# sdio_card_fn1_secure register map
Vendor: Texas Instruments
Peripheral module from a debugger description file (folder CC35X1E).
Registers are 32-bit, access per field, reset 0x0 unless marked. A register's access mark holds for its fields unless they carry their own. Offsets are as the file gives them; lines under a group give offsets from that group; [hi:lo] are bit positions; {n}, {i} and the like mark numbered series; 'fields as' and 'values as' point back to an identical list; <NAME> marks a mode.

## sdio_card_fn1_secure
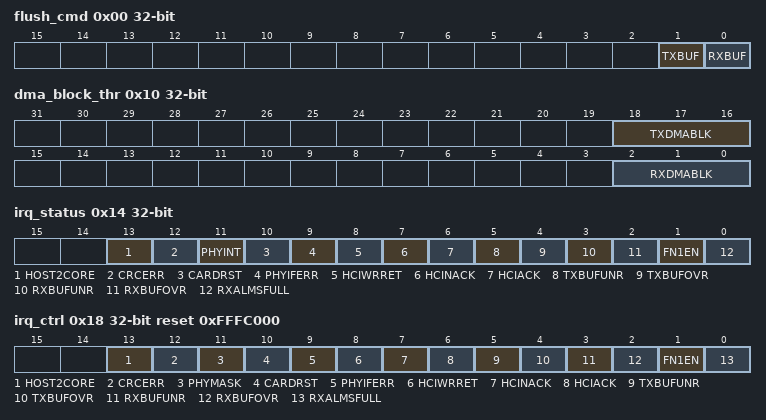
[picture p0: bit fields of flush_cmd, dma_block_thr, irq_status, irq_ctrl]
0x00 flush_cmd — A write only register. Flush command of the RX / TX buffers
  [1] TXBUF wo — TX BUFFER FLUSH: Writing to this address triggers the flush command of the TX buffer (data value is irrelevant).
  [0] RXBUF wo — RX BUFFER FLUSH: Writing to this address triggers the flush command of the RX buffer (data value is irrelevant).
0x04 rx_full_thr reset 0x410 — A R/W register that stores one of the RX buffer thresholds.
  [7:2] VAL rw — Buffer almost full threshold - When passing threshold an interrupt is generated (used by the software to indicate packets in buffer) The threshold is configured to allow receiving a completer packet header including packet length. Typical packet header could be 1 - 128 Bytes however the threshold must be 32bits aligned since SDIO FIFO supports 32bits aligned read only.
0x0C tx_irq_trig_thr reset 0x8080 — TX IRQ TRIG THR: A R/W register that stores the Threshold in bytes to raise host irq.
  [7:0] VAL rw — 8-bit value describing the number of bytes needed to trigger host irq 1. If HCI packet length > SDIO block (128-bytes) trigger is set to 128 Byte (entire block) 2. If HCI packet length < SDIO block, FW sets packet length in bytes as the trigger value
0x10 dma_block_thr reset not defined — A R/W register setting the BLOCK SIZE for the RX and TX DMA flow control
  [18:16] TXDMABLK rw — TX DMA BLOCK SIZE SEL: HOST reads from FIFO Determine when to assert flow control to DMA. The flow should be asserted when FIFO has enough free buffer >= Threshold. The threshold is determined according to the DMA block size 0 - 4 Bytes 1 - 8 Bytes 2 - 16 Bytes (Default) 3 - 32 Bytes 4 - 64 Bytes 5 - 128 Bytes 6,7 - Reserved
  [2:0] RXDMABLK rw — RX DMA BLOCK SIZE SEL: HOST Writes to FIFO Determine when to assert flow control to DMA. The flow should be asserted when num of bytes in FIFO > Threshold. The threshold is determined according to the DMA block size 0 - 4 Bytes 1 - 8 Bytes 2 - 16 Bytes (Default) 3 - 32 Bytes 4 - 64 Bytes 5 - 128 Bytes 6,7 - Reserved HOST Writes to FIFO Determine when to assert flow control to DMA. The flow should be asserted when num of bytes in FIFO > Threshold. The threshold is determined according to the DMA block size 0 - 4 Bytes 1 - 8 Bytes 2 - 16 Bytes (Default) 3 - 32 Bytes 4 - 64 Bytes 5 - 128 Bytes 6,7 - Reserved
0x14 irq_status ro — A RO register. Holds the status of the different interrupts of the SDIO. This register is cleared by writing to IRQ_CLEAR register Each interrupt is set when the event is active. In the case of ACKINT the software has to read the ACKNAK bit value to see if an ACK event was received or a read retry is starting.
  [13] HOST2CORE — Host to Card 15 bit message ready indication
  [12] CRCERR — '1' = CRC Error was detected for rx flow
  [11] PHYINT — SDIO PHY interrupt
  [10] CARDRST — Card Reset interrupt
  [9] PHYIFERR — Error in the OCP interface of the SDIO PHY
  [8] HCIWRRET — HCI packet write retry
  [7] HCINACK — HCI packet NACK interrupt
  [6] HCIACK — HCI packet ACK interrupt
  [5] TXBUFUNR — TX Buffer under-run interrupt
  [4] TXBUFOVR — TX Buffer overrun interrupt
  [3] RXBUFUNR — RX Buffer under-run interrupt
  [2] RXBUFOVR — RX Buffer overrun interrupt
  [1] FN1EN — Function #1 enable interrupt
  [0] RXALMSFULL — RX Buffer almost full interrupt
0x18 irq_ctrl reset 0xFFFC000 (reset mask 0xFFFFC000) — A R/W register. Holds the mask bits of the different interrupts of the SDIO.
  [13] HOST2CORE rw — Host to Card 15 bit message ready indication
  [12] CRCERR rw — '1' = CRC Error was detected for rx flow
  [11] PHYMASK rw — SDIO PHY interrupt
  [10] CARDRST rw — Card Reset interrupt
  [9] PHYIFERR rw — Error in the OCP interface of the SDIO PHY
  [8] HCIWRRET rw — HCI packet write retry
  [7] HCINACK rw — HCI packet NACK interrupt
  [6] HCIACK rw — HCI packet ACK interrupt
  [5] TXBUFUNR rw — TX Buffer under-run interrupt
  [4] TXBUFOVR rw — TX Buffer overrun interrupt
  [3] RXBUFUNR rw — RX Buffer under-run interrupt
  [2] RXBUFOVR rw — RX Buffer overrun interrupt
  [1] FN1EN rw — Function #1 enable interrupt
  [0] RXALMSFULL rw — RX Buffer almost full interrupt
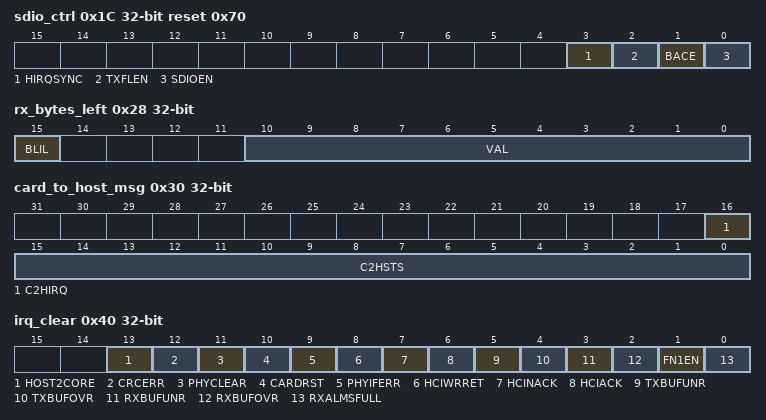
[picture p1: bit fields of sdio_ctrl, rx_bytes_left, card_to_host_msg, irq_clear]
0x1C sdio_ctrl reset 0x70 (reset mask 0xFFFFFFF0) — A R/W register to control SDIO operation.
  [3] HIRQSYNC rw — HOST IRQ SYNCHRONIZATION: This bit controls the synchronization of the host interrupt (interrupt from BT to host through the PHY). '1' - interrupt is synchronized to sdio_clk. '0' - interrupt is not synchronized to sdio_clk (and thus synchronized to ocp_clk)
  [2] TXFLEN rw — TX BUFFER FLUSH ENABLE: Enables the module to flush the TX buffer after receiving packet-read-retry indication (ACK or NACK). When this bit is '0', FW must flush the buffer manually (by writing to FLUSH_CMD register) upon receiving ACK/NACK interrupt. It is needed for the correct operation of the TX FIFO
  [1] BACE rw — BUSY AFTER CRC ERROR: Enables the module to activate the busy signal after CRC error on data only if sdio_enable was set
  [0] SDIOEN rw — SDIO enable - Enable SDIO after CRC error. Cleared by HW after CRC error; Set by FW to de-assert the busy signal
0x20 rx_sdio_packet_size ro — RX SDIO PACKET SIZE: A read only register. Holds the length of the current received SDIO packet. Updated at the beginning of each SDIO packet.
  [9:0] VAL — Length of the current received SDIO packet. Updated at the beginning of each SDIO packet
0x24 rx_bytes_in_buf ro — RX BYTES IN BUFF: A read only status register. Holds the current number of bytes in SDIO RX buffer.
  [10:0] VAL — Current number of bytes in SDIO RX buffer
0x28 rx_bytes_left ro — RX BYTES LEFT: A read only status register. A down-count counter. Holds the number of bytes in current SDIO packet that were not transmitted to RX buffer yet. Please notice: Before reading this register, the FW MUST read RX_BYTES_IN_BUFFER register.
  [15] BLIL — BYTES LEFT IS LOCKED: When '0' - the value that is read from rx_bytes_left is the current number of bytes left to transfer to the end of the block. When '1' - the value that is read from rx_bytes_left is the number of bytes left to transfer to the end of the block that was locked on the last read from RX_BYTES_IN_BUF.
  [10:0] VAL — A counter that is loaded with SDIO packet length and decremented the same as the incrementing of bytes-in-buffer status register
0x2C retry_ctrl reset 0x3 — A read/write register. The value states if the BT-SDIO is working with Retry Control mechanism as specified in SDIO spec.
  [0] VAL rw — When FW writes '1' to this bit, it states that the BT-SDIO is using retry control mechanism. When FW reads this bit, it actually reads the value of the Function 1's RETRY_CONTROL register (the value that the host configured). Default value is '1' because BT FW MUST have retry control mechanism working
0x30 card_to_host_msg — IRQ2Host Message 16b
  [16] C2HIRQ wo — CARD TO HOST IRQ: To Host: 16bits MMR which can be written/read by M33 and read/clear (bit map) by host
  [15:0] C2HSTS rw — CARD TO HOST STS: To Host: 16bits MMR which can be written/read by M33 and read/clear (bit map) by host Cleared by HOST writing to CLINTERD (Interrupt Clear 0x13)
0x34 host_to_card_msg ro — IRQ from Host to card Message 16b
  [14:0] H2CSTS — HOST TO CARD STS: From Host: 15bits MMR which can be written by host and read/clear (bit map) by M33. (bit 16 is the host_to_card_irq that is generated by the HOST and goes to [IRQ_STATUS.HOST_TO_CARD_INT])
0x38 sdio_clk_disable — Clock gating control
  [0] VAL rw — 1'b0 - disable clk 1'b1 - enable clk
0x3C sdio_spare — A read/write 8-bit register that serves for future debug only.
  [7:0] SPARE rw
0x40 irq_clear — A write-only register. When written, it clears all SDIO pending interrupts
  [13] HOST2CORE wo — Host to Card 15 bit message ready indication
  [12] CRCERR wo — CRC Error clear
  [11] PHYCLEAR wo — SDIO PHY interrupt clear
  [10] CARDRST wo — Card Reset interrupt clear
  [9] PHYIFERR wo — Error in the OCP interface of the SDIO PHY clear
  [8] HCIWRRET wo — HCI packet write retry clear
  [7] HCINACK wo — HCI packet NACK interrupt clear
  [6] HCIACK wo — HCI packet ACK interrupt clear
  [5] TXBUFUNR wo — TX Buffer under-run interrupt clear
  [4] TXBUFOVR wo — TX Buffer overrun interrupt clear
  [3] RXBUFUNR wo — RX Buffer under-run interrupt clear
  [2] RXBUFOVR wo — RX Buffer overrun interrupt clear
  [1] FN1EN wo — Function #1 enable interrupt
  [0] RXALMSFULL wo — RX Buffer almost full interrupt clear
0x44 mem_sdio_reset_req — reset sdio IP due to a SDIO Card Reset command: 0 - do not reset / de-assert initiated sdio reset 1 - initiate reset sdio reset (both PHY and SDIO System)
  [0] EN rw — Function #1 enable interrupt
0x1000 sdio_data_fifo rw — Common shadow register to access SDIO-Card RX-Fifo or TX-Fifo
  [31:0] RDRXWRTX — Common access for either: 1. Reading 'sdio_rxfifo' 2. Writing 'sdio_txfifo' Can be used either as local ocp rd/wr commands, or transactions through DMA machine.
